VERSION "HIPBNYYYYYYYYYYYYYYYYYYYYYYYYYYYYYYYYYYYYY/4/%%%/4/'%**4YYY///"

NS_ :

BS_:

BU_: EW_CAN0 ME_AWS_CANA
VAL_TABLE_ Vt_request_type 3 "mute" 2 "get" 1 "up" 0 "down" ;
VAL_TABLE_ Vt_reply_status 2 "reject" 1 "done" 0 "fail" ;
VAL_TABLE_ Vt_ON_OFF 1 "on" 0 "off" ;

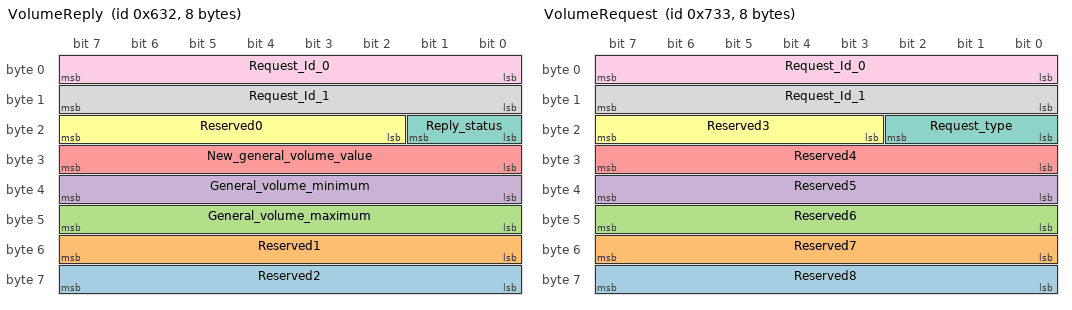
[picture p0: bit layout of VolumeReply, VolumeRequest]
BO_ 1586 VolumeReply: 8 ME_AWS_CANA
 SG_ Reserved2 : 56|8@1+ (1,0) [255|255] "" Vector__XXX
 SG_ Reserved1 : 48|8@1+ (1,0) [255|255] "" Vector__XXX
 SG_ General_volume_maximum : 40|8@1+ (1,0) [0|5] "" Vector__XXX
 SG_ General_volume_minimum : 32|8@1+ (1,0) [0|5] "" Vector__XXX
 SG_ New_general_volume_value : 24|8@1+ (1,0) [0|5] "" Vector__XXX
 SG_ Reserved0 : 18|6@1+ (1,0) [63|63] "" Vector__XXX
 SG_ Reply_status : 16|2@1+ (1,0) [0|2] "enum" Vector__XXX
 SG_ Request_Id_1 : 8|8@1+ (1,0) [0|255] "" Vector__XXX
 SG_ Request_Id_0 : 0|8@1+ (1,0) [0|255] "" Vector__XXX

BO_ 1843 VolumeRequest: 8 EW_CAN0
 SG_ Reserved8 : 56|8@1+ (1,0) [255|255] "" Vector__XXX
 SG_ Reserved7 : 48|8@1+ (1,0) [255|255] "" Vector__XXX
 SG_ Reserved6 : 40|8@1+ (1,0) [255|255] "" Vector__XXX
 SG_ Reserved5 : 32|8@1+ (1,0) [255|255] "" Vector__XXX
 SG_ Reserved4 : 24|8@1+ (1,0) [255|255] "" Vector__XXX
 SG_ Reserved3 : 19|5@1+ (1,0) [31|31] "" Vector__XXX
 SG_ Request_type : 16|3@1+ (1,0) [0|3] "enum" Vector__XXX
 SG_ Request_Id_1 : 8|8@1+ (1,0) [0|255] "" Vector__XXX
 SG_ Request_Id_0 : 0|8@1+ (1,0) [0|255] "" Vector__XXX

VAL_ 1985 Reply_status 2 "reject" 1 "done" 0 "fail" ;
VAL_ 1984 Request_type 3 "mute" 2 "get" 1 "up" 0 "down" ;
